AUTOSAR XML (schema 3.1.2)
package /Components/SWC_PnmAct
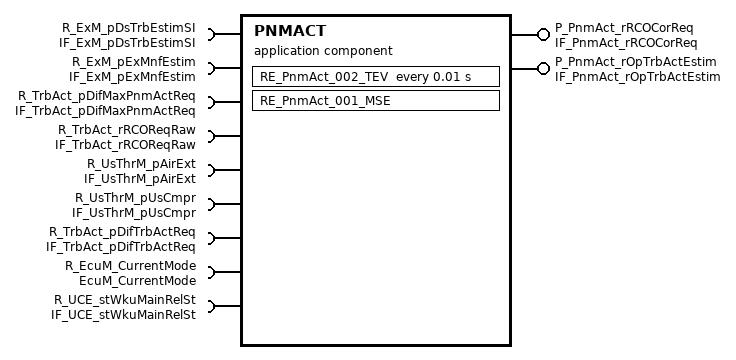
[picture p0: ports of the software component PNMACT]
  application software component type PNMACT
    9 x require port:
      R_ExM_pDsTrbEstimSI: unqueued-receiver-com-spec{data-element=ExM_pDsTrbEstimSI, init-value=ConstantValue, resync-time=0}, required-interface=IF_ExM_pDsTrbEstimSI  # Receiver of interface IF_ExM_pDsTrbEstimSI - Requirement Reference: [01552_12_10165-PnmAct-I003(0)]
      R_ExM_pExMnfEstim: unqueued-receiver-com-spec{data-element=ExM_pExMnfEstim, init-value=ConstantValue1, resync-time=0}, required-interface=IF_ExM_pExMnfEstim  # Receiver of interface IF_ExM_pExMnfEstim - Requirement Reference: [01552_12_10165-PnmAct-I004(0)]
      R_TrbAct_pDifMaxPnmActReq: unqueued-receiver-com-spec{data-element=TrbAct_pDifMaxPnmActReq, init-value=ConstantValue3, resync-time=0}, required-interface=IF_TrbAct_pDifMaxPnmActReq  # Receiver of interface IF_TrbAct_pDifMaxPnmActReq - Requirement Reference: [01552_12_10165-PnmAct-I005(0)]
      R_TrbAct_rRCOReqRaw: unqueued-receiver-com-spec{data-element=TrbAct_rRCOReqRaw, init-value=ConstantValue5, resync-time=0}, required-interface=IF_TrbAct_rRCOReqRaw  # Receiver of interface IF_TrbAct_rRCOReqRaw - Requirement Reference: [01552_12_10165-PnmAct-I006(0)]
      R_UsThrM_pAirExt: unqueued-receiver-com-spec{data-element=UsThrM_pAirExt, init-value=ConstantValue7, resync-time=0}, required-interface=IF_UsThrM_pAirExt  # Receiver of interface IF_UsThrM_pAirExt - Requirement Reference: [01552_12_10165-PnmAct-I007(0)]
      R_UsThrM_pUsCmpr: unqueued-receiver-com-spec{data-element=UsThrM_pUsCmpr, init-value=ConstantValue9, resync-time=0}, required-interface=IF_UsThrM_pUsCmpr  # Receiver of interface IF_UsThrM_pUsCmpr - Requirement Reference: [01552_12_10165-PnmAct-I008(0)]
      R_TrbAct_pDifTrbActReq: unqueued-receiver-com-spec{data-element=TrbAct_pDifTrbActReq, init-value=ConstantValue11, resync-time=0}, required-interface=IF_TrbAct_pDifTrbActReq  # Receiver of interface IF_TrbAct_pDifTrbActReq - Requirement Reference: [01552_12_10165-PnmAct-I009(0)]
      R_EcuM_CurrentMode: required-interface=EcuM_CurrentMode
      R_UCE_stWkuMainRelSt: required-interface=IF_UCE_stWkuMainRelSt
    provide port P_PnmAct_rRCOCorReq: unqueued-sender-com-spec{data-element=PnmAct_rRCOCorReq, can-invalidate=false, init-value=PnmAct_rRCOCorReq_Cst}, provided-interface=IF_PnmAct_rRCOCorReq
    provide port P_PnmAct_rOpTrbActEstim: unqueued-sender-com-spec{data-element=PnmAct_rOpTrbActEstim, can-invalidate=false, init-value=PnmAct_rOpTrbActEstim_Cst}, provided-interface=IF_PnmAct_rOpTrbActEstim
  9 x constant specification:
    ConstantValue
      value:
        integer literal ConstantValue: type=DT_ExM_pDsTrbEstimSI, value=0
    ConstantValue1
      value:
        integer literal ConstantValue1: type=DT_ExM_pExMnfEstim, value=0
    ConstantValue11
      value:
        integer literal ConstantValue11: type=DT_TrbAct_pDifTrbActReq, value=0
    ConstantValue3
      value:
        integer literal ConstantValue3: type=DT_TrbAct_pDifMaxPnmActReq, value=0
    ConstantValue5
      value:
        integer literal ConstantValue5: type=DT_TrbAct_rRCOReqRaw, value=0
    ConstantValue7
      value:
        integer literal ConstantValue7: type=DT_UsThrM_pAirExt, value=0
    ConstantValue9
      value:
        integer literal ConstantValue9: type=DT_UsThrM_pUsCmpr, value=0
    PnmAct_rOpTrbActEstim_Cst
      value:
        integer literal PnmAct_rOpTrbActEstim_Cst: type=DT_PnmAct_rOpTrbActEstim, value=0
    PnmAct_rRCOCorReq_Cst
      value:
        integer literal PnmAct_rRCOCorReq_Cst: type=DT_PnmAct_rRCOCorReq, value=-32767
  internal behavior IB_PnmAct: component=PNMACT
    timing event EV_PnmAct_002_TEV: start-on-event=RE_PnmAct_002_TEV, period=0.01
    mode switch event EV_PnmAct_001_MSE: start-on-event=RE_PnmAct_001_MSE, activation=ENTRY, mode=R_EcuM_CurrentMode.currentMode.RUN
    runnable RE_PnmAct_001_MSE  # 01552_12_10165-PnmAct-A001(0)
      data send point ds_PnmAct_rRCOCorReq: data-element=P_PnmAct_rRCOCorReq.PnmAct_rRCOCorReq
      data send point ds_PnmAct_rOpTrbActEstim: data-element=P_PnmAct_rOpTrbActEstim.PnmAct_rOpTrbActEstim
    runnable RE_PnmAct_002_TEV  # 01552_12_10165-PnmAct-A002(0)
      7 x data receive point:
        dr_TrbAct_pDifTrbActReq: data-element=R_TrbAct_pDifTrbActReq.TrbAct_pDifTrbActReq
        dr_ExM_pDsTrbEstimSI: data-element=R_ExM_pDsTrbEstimSI.ExM_pDsTrbEstimSI
        dr_TrbAct_rRCOReqRaw: data-element=R_TrbAct_rRCOReqRaw.TrbAct_rRCOReqRaw
        dr_UsThrM_pUsCmpr: data-element=R_UsThrM_pUsCmpr.UsThrM_pUsCmpr
        dr_ExM_pExMnfEstim: data-element=R_ExM_pExMnfEstim.ExM_pExMnfEstim
        dr_TrbAct_pDifMaxPnmActReq: data-element=R_TrbAct_pDifMaxPnmActReq.TrbAct_pDifMaxPnmActReq
        dr_UsThrM_pAirExt: data-element=R_UsThrM_pAirExt.UsThrM_pAirExt
      data send point ds_PnmAct_rRCOCorReq: data-element=P_PnmAct_rRCOCorReq.PnmAct_rRCOCorReq
      data send point ds_PnmAct_rOpTrbActEstim: data-element=P_PnmAct_rOpTrbActEstim.PnmAct_rOpTrbActEstim
  swc implementation Imp_PnmAct: programming-language=C, behavior=IB_PnmAct
    code-descriptors:
      code CodeDescriptor: type=SRC
        7 x xfile:
          PnmAct_002_TEV_fct_h: url=PnmAct_002_TEV_fct.h
          PnmAct_calibrations_c: url=PnmAct_calibrations.c
          PnmAct_MemMap_h: url=PnmAct_MemMap.h
          PnmAct_002_TEV_fct_c: url=PnmAct_002_TEV_fct.c
          PnmAct_h: url=PnmAct.h
          PnmAct_c: url=PnmAct.c
          PnmAct_calibrations_h: url=PnmAct_calibrations.h
